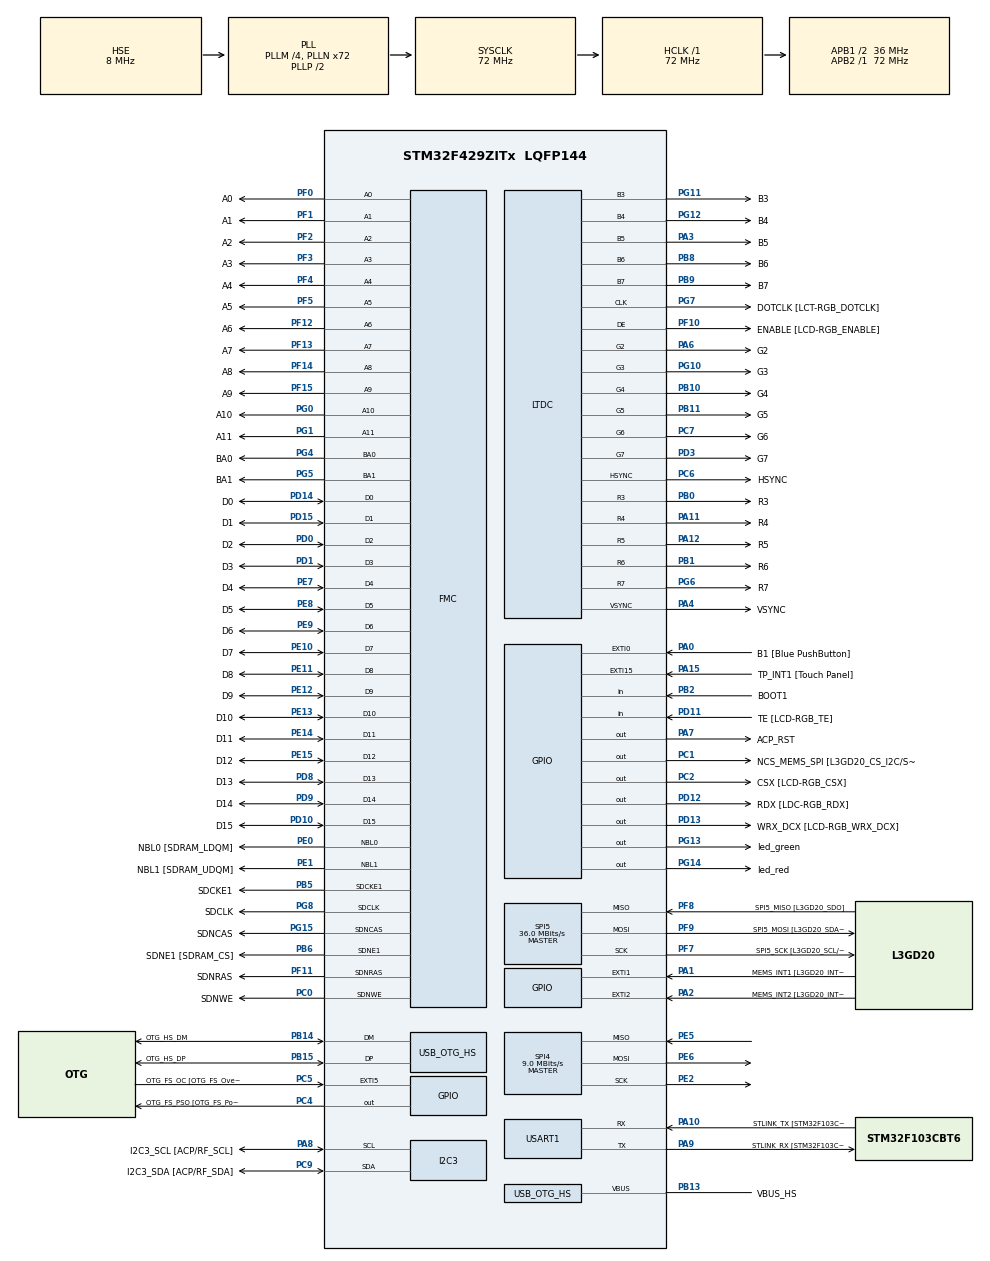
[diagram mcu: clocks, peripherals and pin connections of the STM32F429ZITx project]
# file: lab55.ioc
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FREERTOS.Tasks01=defaultTask,0,128,StartDefaultTask,Default,NULL,Dynamic,NULL,NULL
Mcu.Family=STM32F4
Mcu.Name=STM32F429ZITx
Mcu.Package=LQFP144
NVIC.OTG_HS_IRQn=true\:0\:0\:false\:false\:true\:true\:true\:true
NVIC.PriorityGroup=NVIC_PRIORITYGROUP_4
PA0/WKUP.GPIO_Label=B1 [Blue PushButton]
PA0/WKUP.GPIO_ModeDefaultEXTI=GPIO_MODE_EVT_RISING
PA0/WKUP.GPIO_PuPd=GPIO_NOPULL
PA0/WKUP.Signal=GPXTI0
PA1.GPIO_Label=MEMS_INT1 [L3GD20_INT1]
PA1.GPIO_ModeDefaultEXTI=GPIO_MODE_EVT_RISING
PA1.GPIO_PuPd=GPIO_NOPULL
PA1.Signal=GPXTI1
PA10.GPIO_Label=STLINK_TX [STM32F103CBT6_PA2]
PA10.Mode=Asynchronous
PA10.Signal=USART1_RX
PA11.GPIO_Label=R4
PA11.GPIO_Mode=GPIO_MODE_AF_PP
PA11.GPIO_PuPd=GPIO_NOPULL
PA11.GPIO_Speed=GPIO_SPEED_FREQ_LOW
PA11.Mode=RGB565
PA11.Signal=LTDC_R4
PA12.GPIO_Label=R5
PA12.GPIO_Mode=GPIO_MODE_AF_PP
PA12.GPIO_PuPd=GPIO_NOPULL
PA12.GPIO_Speed=GPIO_SPEED_FREQ_LOW
PA12.Mode=RGB565
PA12.Signal=LTDC_R5
PA13.GPIO_Label=SWDIO
PA13.Mode=Trace_Asynchronous_SW
PA13.Signal=SYS_JTMS-SWDIO
PA14.GPIO_Label=SWCLK
PA14.Mode=Trace_Asynchronous_SW
PA14.Signal=SYS_JTCK-SWCLK
PA15.GPIO_Label=TP_INT1 [Touch Panel]
PA15.GPIO_ModeDefaultEXTI=GPIO_MODE_EVT_RISING
PA15.GPIO_PuPd=GPIO_NOPULL
PA15.Signal=GPXTI15
PA2.GPIO_Label=MEMS_INT2 [L3GD20_INT2]
PA2.GPIO_ModeDefaultEXTI=GPIO_MODE_EVT_RISING
PA2.GPIO_PuPd=GPIO_NOPULL
PA2.Signal=GPXTI2
PA3.GPIO_Label=B5
PA3.GPIO_Mode=GPIO_MODE_AF_PP
PA3.GPIO_PuPd=GPIO_NOPULL
PA3.GPIO_Speed=GPIO_SPEED_FREQ_LOW
PA3.Mode=RGB565
PA3.Signal=LTDC_B5
PA4.GPIO_Label=VSYNC
PA4.GPIO_Mode=GPIO_MODE_AF_PP
PA4.GPIO_PuPd=GPIO_NOPULL
PA4.GPIO_Speed=GPIO_SPEED_FREQ_LOW
PA4.Mode=RGB565
PA4.Signal=LTDC_VSYNC
PA6.GPIO_Label=G2
PA6.GPIO_Mode=GPIO_MODE_AF_PP
PA6.GPIO_PuPd=GPIO_NOPULL
PA6.GPIO_Speed=GPIO_SPEED_FREQ_LOW
PA6.Mode=RGB565
PA6.Signal=LTDC_G2
PA7.GPIO_Label=ACP_RST
PA7.GPIO_Mode=GPIO_MODE_OUTPUT_PP
PA7.GPIO_PuPd=GPIO_NOPULL
PA7.GPIO_Speed=GPIO_SPEED_FREQ_LOW
PA7.Signal=GPIO_Output
PA8.GPIO_Label=I2C3_SCL [ACP/RF_SCL]
PA8.GPIO_Mode=GPIO_MODE_AF_OD
PA8.GPIO_Pu=GPIO_PULLUP
PA8.GPIO_PuPd=GPIO_NOPULL
PA8.GPIO_Speed=GPIO_SPEED_FREQ_LOW
PA8.Mode=I2C
PA8.Signal=I2C3_SCL
PA9.GPIO_Label=STLINK_RX [STM32F103CBT6_PA3]
PA9.Mode=Asynchronous
PA9.Signal=USART1_TX
PB0.GPIO_Label=R3
PB0.GPIO_Mode=GPIO_MODE_AF_PP
PB0.GPIO_PuPd=GPIO_NOPULL
PB0.GPIO_Speed=GPIO_SPEED_FREQ_LOW
PB0.Mode=RGB565
PB0.Signal=LTDC_R3
PB1.GPIO_Label=R6
PB1.GPIO_Mode=GPIO_MODE_AF_PP
PB1.GPIO_PuPd=GPIO_NOPULL
PB1.GPIO_Speed=GPIO_SPEED_FREQ_LOW
PB1.Mode=RGB565
PB1.Signal=LTDC_R6
PB10.GPIO_Label=G4
PB10.GPIO_Mode=GPIO_MODE_AF_PP
PB10.GPIO_PuPd=GPIO_NOPULL
PB10.GPIO_Speed=GPIO_SPEED_FREQ_LOW
PB10.Mode=RGB565
PB10.Signal=LTDC_G4
PB11.GPIO_Label=G5
PB11.GPIO_Mode=GPIO_MODE_AF_PP
PB11.GPIO_PuPd=GPIO_NOPULL
PB11.GPIO_Speed=GPIO_SPEED_FREQ_LOW
PB11.Mode=RGB565
PB11.Signal=LTDC_G5
PB12.GPIO_Label=OTG_HS_ID
PB12.GPIO_Mode=GPIO_MODE_AF_PP
PB12.GPIO_PuPd=GPIO_NOPULL
PB12.GPIO_Speed=GPIO_SPEED_FREQ_LOW
PB12.Signal=USB_OTG_HS_ID
PB13.GPIO_Label=VBUS_HS
PB13.GPIO_Mode=GPIO_MODE_INPUT
PB13.GPIO_PuPd=GPIO_NOPULL
PB13.Mode=Activate_VBUS_FS
PB13.Signal=USB_OTG_HS_VBUS
PB14.GPIO_Label=OTG_HS_DM
PB14.GPIO_Mode=GPIO_MODE_AF_PP
PB14.GPIO_PuPd=GPIO_NOPULL
PB14.GPIO_Speed=GPIO_SPEED_FREQ_LOW
PB14.Mode=Host_FS
PB14.Signal=USB_OTG_HS_DM
PB15.GPIO_Label=OTG_HS_DP
PB15.GPIO_Mode=GPIO_MODE_AF_PP
PB15.GPIO_PuPd=GPIO_NOPULL
PB15.GPIO_Speed=GPIO_SPEED_FREQ_LOW
PB15.Mode=Host_FS
PB15.Signal=USB_OTG_HS_DP
PB2/BOOT1.GPIO_Label=BOOT1
PB2/BOOT1.GPIO_Mode=GPIO_MODE_INPUT
PB2/BOOT1.GPIO_PuPd=GPIO_NOPULL
PB2/BOOT1.Signal=GPIO_Input
PB3.Mode=Trace_Asynchronous_SW
PB3.Signal=SYS_JTDO-SWO
PB5.GPIO_Label=SDCKE1
PB5.GPIO_Mode=GPIO_MODE_AF_PP
PB5.GPIO_PuPd=GPIO_NOPULL
PB5.GPIO_Speed=GPIO_SPEED_FREQ_VERY_HIGH
PB5.Mode=SdramChipSelect2_1
PB5.Signal=FMC_SDCKE1
PB6.GPIO_Label=SDNE1 [SDRAM_CS]
PB6.GPIO_Mode=GPIO_MODE_AF_PP
PB6.GPIO_PuPd=GPIO_NOPULL
PB6.GPIO_Speed=GPIO_SPEED_FREQ_VERY_HIGH
PB6.Mode=SdramChipSelect2_1
PB6.Signal=FMC_SDNE1
PB8.GPIO_Label=B6
PB8.GPIO_Mode=GPIO_MODE_AF_PP
PB8.GPIO_PuPd=GPIO_NOPULL
PB8.GPIO_Speed=GPIO_SPEED_FREQ_LOW
PB8.Mode=RGB565
PB8.Signal=LTDC_B6
PB9.GPIO_Label=B7
PB9.GPIO_Mode=GPIO_MODE_AF_PP
PB9.GPIO_PuPd=GPIO_NOPULL
PB9.GPIO_Speed=GPIO_SPEED_FREQ_LOW
PB9.Mode=RGB565
PB9.Signal=LTDC_B7
PC0.GPIO_Label=SDNWE
PC0.GPIO_Mode=GPIO_MODE_AF_PP
PC0.GPIO_PuPd=GPIO_NOPULL
PC0.GPIO_Speed=GPIO_SPEED_FREQ_VERY_HIGH
PC0.Signal=FMC_SDNWE
PC1.GPIO_Label=NCS_MEMS_SPI [L3GD20_CS_I2C/SPI]
PC1.GPIO_Mode=GPIO_MODE_OUTPUT_PP
PC1.GPIO_PuPd=GPIO_NOPULL
PC1.GPIO_Speed=GPIO_SPEED_FREQ_LOW
PC1.Signal=GPIO_Output
PC10.GPIO_Label=R2
PC10.GPIO_Mode=GPIO_MODE_AF_PP
PC10.GPIO_PuPd=GPIO_NOPULL
PC10.GPIO_Speed=GPIO_SPEED_FREQ_LOW
PC10.Signal=LTDC_R2
PC14/OSC32_IN.GPIO_Label=PC14-OSC32_IN
PC14/OSC32_IN.Signal=RCC_OSC32_IN
PC15/OSC32_OUT.GPIO_Label=PC15-OSC32_OUT
PC15/OSC32_OUT.Signal=RCC_OSC32_OUT
PC2.GPIO_Label=CSX [LCD-RGB_CSX]
PC2.GPIO_Mode=GPIO_MODE_OUTPUT_PP
PC2.GPIO_PuPd=GPIO_NOPULL
PC2.GPIO_Speed=GPIO_SPEED_FREQ_LOW
PC2.Signal=GPIO_Output
PC4.GPIO_Label=OTG_FS_PSO [OTG_FS_PowerSwitchOn]
PC4.GPIO_Mode=GPIO_MODE_OUTPUT_PP
PC4.GPIO_PuPd=GPIO_NOPULL
PC4.GPIO_Speed=GPIO_SPEED_FREQ_LOW
PC4.Signal=GPIO_Output
PC5.GPIO_Label=OTG_FS_OC [OTG_FS_OverCurrent]
PC5.GPIO_ModeDefaultEXTI=GPIO_MODE_EVT_RISING
PC5.Signal=GPXTI5
PC6.GPIO_Label=HSYNC
PC6.GPIO_Mode=GPIO_MODE_AF_PP
PC6.GPIO_PuPd=GPIO_NOPULL
PC6.GPIO_Speed=GPIO_SPEED_FREQ_LOW
PC6.Mode=RGB565
PC6.Signal=LTDC_HSYNC
PC7.GPIO_Label=G6
PC7.GPIO_Mode=GPIO_MODE_AF_PP
PC7.GPIO_PuPd=GPIO_NOPULL
PC7.GPIO_Speed=GPIO_SPEED_FREQ_LOW
PC7.Mode=RGB565
PC7.Signal=LTDC_G6
PC9.GPIO_Label=I2C3_SDA [ACP/RF_SDA]
PC9.GPIO_Mode=GPIO_MODE_AF_OD
PC9.GPIO_Pu=GPIO_PULLUP
PC9.GPIO_PuPd=GPIO_NOPULL
PC9.GPIO_Speed=GPIO_SPEED_FREQ_LOW
PC9.Mode=I2C
PC9.Signal=I2C3_SDA
PD0.GPIO_Label=D2
PD0.GPIO_Mode=GPIO_MODE_AF_PP
PD0.GPIO_PuPd=GPIO_NOPULL
PD0.GPIO_Speed=GPIO_SPEED_FREQ_VERY_HIGH
PD0.Signal=FMC_D2_DA2
PD1.GPIO_Label=D3
PD1.GPIO_Mode=GPIO_MODE_AF_PP
PD1.GPIO_PuPd=GPIO_NOPULL
PD1.GPIO_Speed=GPIO_SPEED_FREQ_VERY_HIGH
PD1.Signal=FMC_D3_DA3
PD10.GPIO_Label=D15
PD10.GPIO_Mode=GPIO_MODE_AF_PP
PD10.GPIO_PuPd=GPIO_NOPULL
PD10.GPIO_Speed=GPIO_SPEED_FREQ_VERY_HIGH
PD10.Signal=FMC_D15_DA15
PD11.GPIO_Label=TE [LCD-RGB_TE]
PD11.GPIO_Mode=GPIO_MODE_INPUT
PD11.GPIO_PuPd=GPIO_NOPULL
PD11.Signal=GPIO_Input
PD12.GPIO_Label=RDX [LDC-RGB_RDX]
PD12.GPIO_Mode=GPIO_MODE_OUTPUT_PP
PD12.GPIO_PuPd=GPIO_NOPULL
PD12.GPIO_Speed=GPIO_SPEED_FREQ_LOW
PD12.Signal=GPIO_Output
PD13.GPIO_Label=WRX_DCX [LCD-RGB_WRX_DCX]
PD13.GPIO_Mode=GPIO_MODE_OUTPUT_PP
PD13.GPIO_PuPd=GPIO_NOPULL
PD13.GPIO_Speed=GPIO_SPEED_FREQ_LOW
PD13.Signal=GPIO_Output
PD14.GPIO_Label=D0
PD14.GPIO_Mode=GPIO_MODE_AF_PP
PD14.GPIO_PuPd=GPIO_NOPULL
PD14.GPIO_Speed=GPIO_SPEED_FREQ_VERY_HIGH
PD14.Signal=FMC_D0_DA0
PD15.GPIO_Label=D1
PD15.GPIO_Mode=GPIO_MODE_AF_PP
PD15.GPIO_PuPd=GPIO_NOPULL
PD15.GPIO_Speed=GPIO_SPEED_FREQ_VERY_HIGH
PD15.Signal=FMC_D1_DA1
PD3.GPIO_Label=G7
PD3.GPIO_Mode=GPIO_MODE_AF_PP
PD3.GPIO_PuPd=GPIO_NOPULL
PD3.GPIO_Speed=GPIO_SPEED_FREQ_LOW
PD3.Mode=RGB565
PD3.Signal=LTDC_G7
PD6.GPIO_Label=B2
PD6.GPIO_Mode=GPIO_MODE_AF_PP
PD6.GPIO_PuPd=GPIO_NOPULL
PD6.GPIO_Speed=GPIO_SPEED_FREQ_LOW
PD6.Signal=LTDC_B2
PD8.GPIO_Label=D13
PD8.GPIO_Mode=GPIO_MODE_AF_PP
PD8.GPIO_PuPd=GPIO_NOPULL
PD8.GPIO_Speed=GPIO_SPEED_FREQ_VERY_HIGH
PD8.Signal=FMC_D13_DA13
PD9.GPIO_Label=D14
PD9.GPIO_Mode=GPIO_MODE_AF_PP
PD9.GPIO_PuPd=GPIO_NOPULL
PD9.GPIO_Speed=GPIO_SPEED_FREQ_VERY_HIGH
PD9.Signal=FMC_D14_DA14
PE0.GPIO_Label=NBL0 [SDRAM_LDQM]
PE0.GPIO_Mode=GPIO_MODE_AF_PP
PE0.GPIO_PuPd=GPIO_NOPULL
PE0.GPIO_Speed=GPIO_SPEED_FREQ_VERY_HIGH
PE0.Signal=FMC_NBL0
PE1.GPIO_Label=NBL1 [SDRAM_UDQM]
PE1.GPIO_Mode=GPIO_MODE_AF_PP
PE1.GPIO_PuPd=GPIO_NOPULL
PE1.GPIO_Speed=GPIO_SPEED_FREQ_VERY_HIGH
PE1.Signal=FMC_NBL1
PE10.GPIO_Label=D7
PE10.GPIO_Mode=GPIO_MODE_AF_PP
PE10.GPIO_PuPd=GPIO_NOPULL
PE10.GPIO_Speed=GPIO_SPEED_FREQ_VERY_HIGH
PE10.Signal=FMC_D7_DA7
PE11.GPIO_Label=D8
PE11.GPIO_Mode=GPIO_MODE_AF_PP
PE11.GPIO_PuPd=GPIO_NOPULL
PE11.GPIO_Speed=GPIO_SPEED_FREQ_VERY_HIGH
PE11.Signal=FMC_D8_DA8
PE12.GPIO_Label=D9
PE12.GPIO_Mode=GPIO_MODE_AF_PP
PE12.GPIO_PuPd=GPIO_NOPULL
PE12.GPIO_Speed=GPIO_SPEED_FREQ_VERY_HIGH
PE12.Signal=FMC_D9_DA9
PE13.GPIO_Label=D10
PE13.GPIO_Mode=GPIO_MODE_AF_PP
PE13.GPIO_PuPd=GPIO_NOPULL
PE13.GPIO_Speed=GPIO_SPEED_FREQ_VERY_HIGH
PE13.Signal=FMC_D10_DA10
PE14.GPIO_Label=D11
PE14.GPIO_Mode=GPIO_MODE_AF_PP
PE14.GPIO_PuPd=GPIO_NOPULL
PE14.GPIO_Speed=GPIO_SPEED_FREQ_VERY_HIGH
PE14.Signal=FMC_D11_DA11
PE15.GPIO_Label=D12
PE15.GPIO_Mode=GPIO_MODE_AF_PP
PE15.GPIO_PuPd=GPIO_NOPULL
PE15.GPIO_Speed=GPIO_SPEED_FREQ_VERY_HIGH
PE15.Signal=FMC_D12_DA12
PE2.Mode=Full_Duplex_Master
PE2.Signal=SPI4_SCK
PE5.Mode=Full_Duplex_Master
PE5.Signal=SPI4_MISO
PE6.Mode=Full_Duplex_Master
PE6.Signal=SPI4_MOSI
PE7.GPIO_Label=D4
PE7.GPIO_Mode=GPIO_MODE_AF_PP
PE7.GPIO_PuPd=GPIO_NOPULL
PE7.GPIO_Speed=GPIO_SPEED_FREQ_VERY_HIGH
PE7.Signal=FMC_D4_DA4
PE8.GPIO_Label=D5
PE8.GPIO_Mode=GPIO_MODE_AF_PP
PE8.GPIO_PuPd=GPIO_NOPULL
PE8.GPIO_Speed=GPIO_SPEED_FREQ_VERY_HIGH
PE8.Signal=FMC_D5_DA5
PE9.GPIO_Label=D6
PE9.GPIO_Mode=GPIO_MODE_AF_PP
PE9.GPIO_PuPd=GPIO_NOPULL
PE9.GPIO_Speed=GPIO_SPEED_FREQ_VERY_HIGH
PE9.Signal=FMC_D6_DA6
PF0.GPIO_Label=A0
PF0.GPIO_Mode=GPIO_MODE_AF_PP
PF0.GPIO_PuPd=GPIO_NOPULL
PF0.GPIO_Speed=GPIO_SPEED_FREQ_VERY_HIGH
PF0.Signal=FMC_A0
PF1.GPIO_Label=A1
PF1.GPIO_Mode=GPIO_MODE_AF_PP
PF1.GPIO_PuPd=GPIO_NOPULL
PF1.GPIO_Speed=GPIO_SPEED_FREQ_VERY_HIGH
PF1.Signal=FMC_A1
PF10.GPIO_Label=ENABLE [LCD-RGB_ENABLE]
PF10.GPIO_Mode=GPIO_MODE_AF_PP
PF10.GPIO_PuPd=GPIO_NOPULL
PF10.GPIO_Speed=GPIO_SPEED_FREQ_LOW
PF10.Mode=RGB565
PF10.Signal=LTDC_DE
PF11.GPIO_Label=SDNRAS
PF11.GPIO_Mode=GPIO_MODE_AF_PP
PF11.GPIO_PuPd=GPIO_NOPULL
PF11.GPIO_Speed=GPIO_SPEED_FREQ_VERY_HIGH
PF11.Signal=FMC_SDNRAS
PF12.GPIO_Label=A6
PF12.GPIO_Mode=GPIO_MODE_AF_PP
PF12.GPIO_PuPd=GPIO_NOPULL
PF12.GPIO_Speed=GPIO_SPEED_FREQ_VERY_HIGH
PF12.Signal=FMC_A6
PF13.GPIO_Label=A7
PF13.GPIO_Mode=GPIO_MODE_AF_PP
PF13.GPIO_PuPd=GPIO_NOPULL
PF13.GPIO_Speed=GPIO_SPEED_FREQ_VERY_HIGH
PF13.Signal=FMC_A7
PF14.GPIO_Label=A8
PF14.GPIO_Mode=GPIO_MODE_AF_PP
PF14.GPIO_PuPd=GPIO_NOPULL
PF14.GPIO_Speed=GPIO_SPEED_FREQ_VERY_HIGH
PF14.Signal=FMC_A8
PF15.GPIO_Label=A9
PF15.GPIO_Mode=GPIO_MODE_AF_PP
PF15.GPIO_PuPd=GPIO_NOPULL
PF15.GPIO_Speed=GPIO_SPEED_FREQ_VERY_HIGH
PF15.Signal=FMC_A9
PF2.GPIO_Label=A2
PF2.GPIO_Mode=GPIO_MODE_AF_PP
PF2.GPIO_PuPd=GPIO_NOPULL
PF2.GPIO_Speed=GPIO_SPEED_FREQ_VERY_HIGH
PF2.Signal=FMC_A2
PF3.GPIO_Label=A3
PF3.GPIO_Mode=GPIO_MODE_AF_PP
PF3.GPIO_PuPd=GPIO_NOPULL
PF3.GPIO_Speed=GPIO_SPEED_FREQ_VERY_HIGH
PF3.Signal=FMC_A3
PF4.GPIO_Label=A4
PF4.GPIO_Mode=GPIO_MODE_AF_PP
PF4.GPIO_PuPd=GPIO_NOPULL
PF4.GPIO_Speed=GPIO_SPEED_FREQ_VERY_HIGH
PF4.Signal=FMC_A4
PF5.GPIO_Label=A5
PF5.GPIO_Mode=GPIO_MODE_AF_PP
PF5.GPIO_PuPd=GPIO_NOPULL
PF5.GPIO_Speed=GPIO_SPEED_FREQ_VERY_HIGH
PF5.Signal=FMC_A5
PF7.GPIO_Label=SPI5_SCK [L3GD20_SCL/SPC]
PF7.GPIO_Mode=GPIO_MODE_AF_PP
PF7.GPIO_PuPd=GPIO_NOPULL
PF7.GPIO_Speed=GPIO_SPEED_FREQ_LOW
PF7.Mode=Full_Duplex_Master
PF7.Signal=SPI5_SCK
PF8.GPIO_Label=SPI5_MISO [L3GD20_SDO]
PF8.GPIO_Mode=GPIO_MODE_AF_PP
PF8.GPIO_PuPd=GPIO_NOPULL
PF8.GPIO_Speed=GPIO_SPEED_FREQ_LOW
PF8.Mode=Full_Duplex_Master
PF8.Signal=SPI5_MISO
PF9.GPIO_Label=SPI5_MOSI [L3GD20_SDA/SDI/SDO]
PF9.GPIO_Mode=GPIO_MODE_AF_PP
PF9.GPIO_PuPd=GPIO_NOPULL
PF9.GPIO_Speed=GPIO_SPEED_FREQ_LOW
PF9.Mode=Full_Duplex_Master
PF9.Signal=SPI5_MOSI
PG0.GPIO_Label=A10
PG0.GPIO_Mode=GPIO_MODE_AF_PP
PG0.GPIO_PuPd=GPIO_NOPULL
PG0.GPIO_Speed=GPIO_SPEED_FREQ_VERY_HIGH
PG0.Signal=FMC_A10
PG1.GPIO_Label=A11
PG1.GPIO_Mode=GPIO_MODE_AF_PP
PG1.GPIO_PuPd=GPIO_NOPULL
PG1.GPIO_Speed=GPIO_SPEED_FREQ_VERY_HIGH
PG1.Signal=FMC_A11
PG10.GPIO_Label=G3
PG10.GPIO_Mode=GPIO_MODE_AF_PP
PG10.GPIO_PuPd=GPIO_NOPULL
PG10.GPIO_Speed=GPIO_SPEED_FREQ_LOW
PG10.Mode=RGB565
PG10.Signal=LTDC_G3
PG11.GPIO_Label=B3
PG11.GPIO_Mode=GPIO_MODE_AF_PP
PG11.GPIO_PuPd=GPIO_NOPULL
PG11.GPIO_Speed=GPIO_SPEED_FREQ_LOW
PG11.Mode=RGB565
PG11.Signal=LTDC_B3
PG12.GPIO_Label=B4
PG12.GPIO_Mode=GPIO_MODE_AF_PP
PG12.GPIO_PuPd=GPIO_NOPULL
PG12.GPIO_Speed=GPIO_SPEED_FREQ_LOW
PG12.Mode=RGB565
PG12.Signal=LTDC_B4
PG13.GPIO_Label=led_green
PG13.GPIO_Mode=GPIO_MODE_OUTPUT_PP
PG13.GPIO_PuPd=GPIO_NOPULL
PG13.GPIO_Speed=GPIO_SPEED_FREQ_LOW
PG13.Signal=GPIO_Output
PG14.GPIO_Label=led_red
PG14.GPIO_Mode=GPIO_MODE_OUTPUT_PP
PG14.GPIO_PuPd=GPIO_NOPULL
PG14.GPIO_Speed=GPIO_SPEED_FREQ_LOW
PG14.Signal=GPIO_Output
PG15.GPIO_Label=SDNCAS
PG15.GPIO_Mode=GPIO_MODE_AF_PP
PG15.GPIO_PuPd=GPIO_NOPULL
PG15.GPIO_Speed=GPIO_SPEED_FREQ_VERY_HIGH
PG15.Signal=FMC_SDNCAS
PG4.GPIO_Label=BA0
PG4.GPIO_Mode=GPIO_MODE_AF_PP
PG4.GPIO_PuPd=GPIO_NOPULL
PG4.GPIO_Speed=GPIO_SPEED_FREQ_VERY_HIGH
PG4.Signal=FMC_A14_BA0
PG5.GPIO_Label=BA1
PG5.GPIO_Mode=GPIO_MODE_AF_PP
PG5.GPIO_PuPd=GPIO_NOPULL
PG5.GPIO_Speed=GPIO_SPEED_FREQ_VERY_HIGH
PG5.Signal=FMC_A15_BA1
PG6.GPIO_Label=R7
PG6.GPIO_Mode=GPIO_MODE_AF_PP
PG6.GPIO_PuPd=GPIO_NOPULL
PG6.GPIO_Speed=GPIO_SPEED_FREQ_LOW
PG6.Mode=RGB565
PG6.Signal=LTDC_R7
PG7.GPIO_Label=DOTCLK [LCT-RGB_DOTCLK]
PG7.GPIO_Mode=GPIO_MODE_AF_PP
PG7.GPIO_PuPd=GPIO_NOPULL
PG7.GPIO_Speed=GPIO_SPEED_FREQ_LOW
PG7.Mode=RGB565
PG7.Signal=LTDC_CLK
PG8.GPIO_Label=SDCLK
PG8.GPIO_Mode=GPIO_MODE_AF_PP
PG8.GPIO_PuPd=GPIO_NOPULL
PG8.GPIO_Speed=GPIO_SPEED_FREQ_VERY_HIGH
PG8.Signal=FMC_SDCLK
PH0/OSC_IN.GPIO_Label=PH0-OSC_IN
PH0/OSC_IN.Mode=HSE-External-Oscillator
PH0/OSC_IN.Signal=RCC_OSC_IN
PH1/OSC_OUT.GPIO_Label=PH1-OSC_OUT
PH1/OSC_OUT.Mode=HSE-External-Oscillator
PH1/OSC_OUT.Signal=RCC_OSC_OUT
ProjectManager.HeapSize=0x200
ProjectManager.StackSize=0x400
ProjectManager.TargetToolchain=STM32CubeIDE
RCC.48MHZClocksFreq_Value=48000000
RCC.AHBFreq_Value=72000000
RCC.APB1CLKDivider=RCC_HCLK_DIV2
RCC.APB1Freq_Value=36000000
RCC.APB1TimFreq_Value=72000000
RCC.APB2Freq_Value=72000000
RCC.APB2TimFreq_Value=72000000
RCC.CortexFreq_Value=72000000
RCC.HCLKFreq_Value=72000000
RCC.HSE_VALUE=8000000
RCC.HSI_VALUE=16000000
RCC.LSE_VALUE=32768
RCC.PLLM=4
RCC.PLLN=72
RCC.PLLQ=3
RCC.PLLSAIN=50
RCC.SYSCLKFreq_VALUE=72000000
RCC.SYSCLKSource=RCC_SYSCLKSOURCE_PLLCLK
RCC.VCOOutputFreq_Value=144000000
SH.FMC_A0.0=FMC_A0,12b-sda1
SH.FMC_A1.0=FMC_A1,12b-sda1
SH.FMC_A10.0=FMC_A10,12b-sda1
SH.FMC_A11.0=FMC_A11,12b-sda1
SH.FMC_A14_BA0.0=FMC_BA0,FourSdramBanks1
SH.FMC_A15_BA1.0=FMC_BA1,FourSdramBanks1
SH.FMC_A2.0=FMC_A2,12b-sda1
SH.FMC_A3.0=FMC_A3,12b-sda1
SH.FMC_A4.0=FMC_A4,12b-sda1
SH.FMC_A5.0=FMC_A5,12b-sda1
SH.FMC_A6.0=FMC_A6,12b-sda1
SH.FMC_A7.0=FMC_A7,12b-sda1
SH.FMC_A8.0=FMC_A8,12b-sda1
SH.FMC_A9.0=FMC_A9,12b-sda1
SH.FMC_D0_DA0.0=FMC_D0,sd-16b-d1
SH.FMC_D10_DA10.0=FMC_D10,sd-16b-d1
SH.FMC_D11_DA11.0=FMC_D11,sd-16b-d1
SH.FMC_D12_DA12.0=FMC_D12,sd-16b-d1
SH.FMC_D13_DA13.0=FMC_D13,sd-16b-d1
SH.FMC_D14_DA14.0=FMC_D14,sd-16b-d1
SH.FMC_D15_DA15.0=FMC_D15,sd-16b-d1
SH.FMC_D1_DA1.0=FMC_D1,sd-16b-d1
SH.FMC_D2_DA2.0=FMC_D2,sd-16b-d1
SH.FMC_D3_DA3.0=FMC_D3,sd-16b-d1
SH.FMC_D4_DA4.0=FMC_D4,sd-16b-d1
SH.FMC_D5_DA5.0=FMC_D5,sd-16b-d1
SH.FMC_D6_DA6.0=FMC_D6,sd-16b-d1
SH.FMC_D7_DA7.0=FMC_D7,sd-16b-d1
SH.FMC_D8_DA8.0=FMC_D8,sd-16b-d1
SH.FMC_D9_DA9.0=FMC_D9,sd-16b-d1
SH.FMC_NBL0.0=FMC_NBL0,Sd2ByteEnable1
SH.FMC_NBL1.0=FMC_NBL1,Sd2ByteEnable1
SH.FMC_SDCLK.0=FMC_SDCLK,12b-sda1
SH.FMC_SDNCAS.0=FMC_SDNCAS,12b-sda1
SH.FMC_SDNRAS.0=FMC_SDNRAS,12b-sda1
SH.FMC_SDNWE.0=FMC_SDNWE,12b-sda1
SPI4.BaudRatePrescaler=SPI_BAUDRATEPRESCALER_8
SPI4.CalculateBaudRate=9.0 MBits/s
SPI4.Direction=SPI_DIRECTION_2LINES
SPI4.Mode=SPI_MODE_MASTER
SPI4.VirtualType=VM_MASTER
SPI5.CalculateBaudRate=36.0 MBits/s
SPI5.Direction=SPI_DIRECTION_2LINES
SPI5.Mode=SPI_MODE_MASTER
SPI5.VirtualType=VM_MASTER
USART1.VirtualMode=VM_ASYNC
USB_HOST.USBH_HandleTypeDef-CDC_HS=hUsbHostHS
USB_HOST.VirtualModeHS=Cdc
USB_OTG_HS.VirtualMode-Host_FS=Host_FS
VP_CRC_VS_CRC.Mode=CRC_Activate
VP_DMA2D_VS_DMA2D.Mode=DMA2D_Activate
VP_FREERTOS_VS_CMSIS_V1.Mode=CMSIS_V1
VP_TIM1_VS_ClockSourceINT.Mode=Internal
VP_USB_HOST_VS_USB_HOST_CDC_HS.Mode=CDC_HS
board=STM32F429I-DISC1

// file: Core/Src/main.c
/* USER CODE BEGIN Header */
/**
  ******************************************************************************
  * @file           : main.c
  * @brief          : Main program body
  ******************************************************************************
  * @attention
  *
  * Copyright (c) 2026 STMicroelectronics.
  * All rights reserved.
  *
  * This software is licensed under terms that can be found in the LICENSE file
  * in the root directory of this software component.
  * If no LICENSE file comes with this software, it is provided AS-IS.
  *
  ******************************************************************************
  */
/* USER CODE END Header */
#include "main.h"
#include "cmsis_os.h"
#include "usb_host.h"

/* USER CODE BEGIN Includes */
#include <stdio.h>
#include <string.h>
/* USER CODE END Includes */

/* USER CODE BEGIN PD */
#define CSX_Pin        GPIO_PIN_2
#define WRX_DCX_Pin    GPIO_PIN_13
/* ILI9341 komandos */
#define ILI9341_RESET           0x01
#define ILI9341_SLEEP_OUT       0x11
#define ILI9341_GAMMA           0x26
#define ILI9341_DISPLAY_OFF     0x28
#define ILI9341_DISPLAY_ON      0x29
#define ILI9341_COLUMN_ADDR     0x2A
#define ILI9341_PAGE_ADDR       0x2B
#define ILI9341_GRAM            0x2C
#define ILI9341_MAC             0x36
#define ILI9341_PIXEL_FORMAT    0x3A
#define ILI9341_WDB             0x51
#define ILI9341_WCD             0x53
#define ILI9341_RGB_INTERFACE   0xB0
#define ILI9341_FRC             0xB1
#define ILI9341_BPC             0xB5
#define ILI9341_DFC             0xB6
#define ILI9341_POWER1          0xC0
#define ILI9341_POWER2          0xC1
#define ILI9341_VCOM1           0xC5
#define ILI9341_VCOM2           0xC7
#define ILI9341_POWERA          0xCB
#define ILI9341_POWERB          0xCF
#define ILI9341_PGAMMA          0xE0
#define ILI9341_NGAMMA          0xE1
#define ILI9341_DTCA            0xE8
#define ILI9341_DTCB            0xEA
#define ILI9341_POWER_SEQ       0xED
#define ILI9341_3GAMMA_EN       0xF2
#define ILI9341_INTERFACE       0xF6
#define ILI9341_PRC             0xF7

/* Ekrano dydis */
#define LCD_WIDTH   240
#define LCD_HEIGHT  320

/* Spalvos RGB565 formatu */
#define COLOR_BLACK   0x0000
#define COLOR_WHITE   0xFFFF
#define COLOR_RED     0xF800
#define COLOR_GREEN   0x07E0
#define COLOR_BLUE    0x001F
#define COLOR_YELLOW  0xFFE0
#define COLOR_CYAN    0x07FF
#define COLOR_MAGENTA 0xF81F

/* GPIO – atitinka jūsų MX_GPIO_Init konfigūraciją */
#define LCD_CS_LOW()   HAL_GPIO_WritePin(GPIOC, CSX_Pin,      GPIO_PIN_RESET)
#define LCD_CS_HIGH()  HAL_GPIO_WritePin(GPIOC, CSX_Pin,      GPIO_PIN_SET)
#define LCD_DC_LOW()   HAL_GPIO_WritePin(GPIOD, WRX_DCX_Pin,  GPIO_PIN_RESET)  /* komanda */
#define LCD_DC_HIGH()  HAL_GPIO_WritePin(GPIOD, WRX_DCX_Pin,  GPIO_PIN_SET)    /* duomenys */
#define LCD_RST_LOW()  HAL_GPIO_WritePin(ACP_RST_GPIO_Port, ACP_RST_Pin, GPIO_PIN_RESET)
#define LCD_RST_HIGH() HAL_GPIO_WritePin(ACP_RST_GPIO_Port, ACP_RST_Pin, GPIO_PIN_SET)
/* USER CODE END PD */

CRC_HandleTypeDef hcrc;

DMA2D_HandleTypeDef hdma2d;

I2C_HandleTypeDef hi2c3;

LTDC_HandleTypeDef hltdc;

SPI_HandleTypeDef hspi4;
SPI_HandleTypeDef hspi5;

TIM_HandleTypeDef htim1;

UART_HandleTypeDef huart1;

SDRAM_HandleTypeDef hsdram1;

osThreadId defaultTaskHandle;
/* USER CODE BEGIN PV */
uint8_t tx_data[4] = {8, 12, 13, 15}; // Duomenys, kuriuos siųsime
uint8_t rx_data[4] = {0, 0, 0, 0};     // Čia saugosime tai, ką priimsime
HAL_StatusTypeDef spi_status = HAL_OK;  // add this
/* USER CODE END PV */

void SystemClock_Config(void);
static void MX_GPIO_Init(void);
static void MX_CRC_Init(void);
static void MX_DMA2D_Init(void);
static void MX_FMC_Init(void);
static void MX_I2C3_Init(void);
static void MX_LTDC_Init(void);
static void MX_SPI4_Init(void);
static void MX_SPI5_Init(void);
static void MX_TIM1_Init(void);
static void MX_USART1_UART_Init(void);
void StartDefaultTask(void const * argument);

/* USER CODE BEGIN PFP */
static void LCD_WriteCommand(uint8_t cmd);
static void LCD_WriteData(uint8_t data);
static void LCD_WriteData16(uint16_t data);
static void LCD_Init(void);
static void LCD_SetWindow(uint16_t x0, uint16_t y0, uint16_t x1, uint16_t y1);
static void LCD_FillRect(uint16_t x, uint16_t y, uint16_t w, uint16_t h, uint16_t color);
static void LCD_FillScreen(uint16_t color);
static void LCD_DrawChar(uint16_t x, uint16_t y, char c, uint16_t fg, uint16_t bg, uint8_t size);
static void LCD_DrawString(uint16_t x, uint16_t y, const char *str, uint16_t fg, uint16_t bg, uint8_t size);
static void LCD_DrawPixel(uint16_t x, uint16_t y, uint16_t color);
static void LCD_DrawLine(uint16_t x0, uint16_t y0, uint16_t x1, uint16_t y1, uint16_t color);
static void LCD_DrawRect(uint16_t x, uint16_t y, uint16_t w, uint16_t h, uint16_t color);
static void SPI_Demo_Display(uint8_t *tx, uint8_t *rx, HAL_StatusTypeDef status);
/* USER CODE END PFP */

int main(void)
{

  /* MCU Configuration--------------------------------------------------------*/

  /* Reset of all peripherals, Initializes the Flash interface and the Systick. */
  HAL_Init();

  /* Configure the system clock */
  SystemClock_Config();

  /* Initialize all configured peripherals */
  MX_GPIO_Init();
  MX_CRC_Init();
  MX_DMA2D_Init();
 // MX_FMC_Init();
  MX_I2C3_Init();
 // MX_LTDC_Init();
  MX_SPI4_Init();
  MX_SPI5_Init();
  MX_TIM1_Init();
  MX_USART1_UART_Init();
  /* USER CODE BEGIN 2 */
  HAL_SPI_TransmitReceive(&hspi4, tx_data, rx_data, 4, 100);
  /* USER CODE END 2 */

  /* Create the thread(s) */
  /* definition and creation of defaultTask */
  osThreadDef(defaultTask, StartDefaultTask, osPriorityNormal, 0, 128);
//  defaultTaskHandle = osThreadCreate(osThread(defaultTask), NULL);

  /* USER CODE BEGIN RTOS_THREADS */
  if(defaultTaskHandle == NULL)
      {
          // Task nesukurtas - mirksėkite raudonai
          while(1)
          {
              HAL_GPIO_TogglePin(GPIOG, led_red_Pin);
              HAL_Delay(200);
          }
      }
  /* USER CODE END RTOS_THREADS */

  /* Start scheduler */
  osKernelStart();

  /* We should never get here as control is now taken by the scheduler */

  /* Infinite loop */
  while (1)
  {
	      {
	          HAL_GPIO_TogglePin(GPIOG, led_green_Pin);
	          HAL_Delay(500);
	      }
  }
}

void SystemClock_Config(void)
{
  RCC_OscInitTypeDef RCC_OscInitStruct = {0};
  RCC_ClkInitTypeDef RCC_ClkInitStruct = {0};

  /** Configure the main internal regulator output voltage
  */
  __HAL_RCC_PWR_CLK_ENABLE();
  __HAL_PWR_VOLTAGESCALING_CONFIG(PWR_REGULATOR_VOLTAGE_SCALE3);

  /** Initializes the RCC Oscillators according to the specified parameters
  * in the RCC_OscInitTypeDef structure.
  */
  RCC_OscInitStruct.OscillatorType = RCC_OSCILLATORTYPE_HSE;
  RCC_OscInitStruct.HSEState = RCC_HSE_ON;
  RCC_OscInitStruct.PLL.PLLState = RCC_PLL_ON;
  RCC_OscInitStruct.PLL.PLLSource = RCC_PLLSOURCE_HSE;
  RCC_OscInitStruct.PLL.PLLM = 4;
  RCC_OscInitStruct.PLL.PLLN = 72;
  RCC_OscInitStruct.PLL.PLLP = RCC_PLLP_DIV2;
  RCC_OscInitStruct.PLL.PLLQ = 3;
  if (HAL_RCC_OscConfig(&RCC_OscInitStruct) != HAL_OK)
  {
    Error_Handler();
  }

  /** Initializes the CPU, AHB and APB buses clocks
  */
  RCC_ClkInitStruct.ClockType = RCC_CLOCKTYPE_HCLK|RCC_CLOCKTYPE_SYSCLK
                              |RCC_CLOCKTYPE_PCLK1|RCC_CLOCKTYPE_PCLK2;
  RCC_ClkInitStruct.SYSCLKSource = RCC_SYSCLKSOURCE_PLLCLK;
  RCC_ClkInitStruct.AHBCLKDivider = RCC_SYSCLK_DIV1;
  RCC_ClkInitStruct.APB1CLKDivider = RCC_HCLK_DIV2;
  RCC_ClkInitStruct.APB2CLKDivider = RCC_HCLK_DIV1;

  if (HAL_RCC_ClockConfig(&RCC_ClkInitStruct, FLASH_LATENCY_2) != HAL_OK)
  {
    Error_Handler();
  }
}

static void MX_CRC_Init(void)
{

  hcrc.Instance = CRC;
  if (HAL_CRC_Init(&hcrc) != HAL_OK)
  {
    Error_Handler();
  }

}

static void MX_DMA2D_Init(void)
{

  hdma2d.Instance = DMA2D;
  hdma2d.Init.Mode = DMA2D_M2M;
  hdma2d.Init.ColorMode = DMA2D_OUTPUT_ARGB8888;
  hdma2d.Init.OutputOffset = 0;
  hdma2d.LayerCfg[1].InputOffset = 0;
  hdma2d.LayerCfg[1].InputColorMode = DMA2D_INPUT_ARGB8888;
  hdma2d.LayerCfg[1].AlphaMode = DMA2D_NO_MODIF_ALPHA;
  hdma2d.LayerCfg[1].InputAlpha = 0;
  if (HAL_DMA2D_Init(&hdma2d) != HAL_OK)
  {
    Error_Handler();
  }
  if (HAL_DMA2D_ConfigLayer(&hdma2d, 1) != HAL_OK)
  {
    Error_Handler();
  }

}

static void MX_I2C3_Init(void)
{

  hi2c3.Instance = I2C3;
  hi2c3.Init.ClockSpeed = 100000;
  hi2c3.Init.DutyCycle = I2C_DUTYCYCLE_2;
  hi2c3.Init.OwnAddress1 = 0;
  hi2c3.Init.AddressingMode = I2C_ADDRESSINGMODE_7BIT;
  hi2c3.Init.DualAddressMode = I2C_DUALADDRESS_DISABLE;
  hi2c3.Init.OwnAddress2 = 0;
  hi2c3.Init.GeneralCallMode = I2C_GENERALCALL_DISABLE;
  hi2c3.Init.NoStretchMode = I2C_NOSTRETCH_DISABLE;
  if (HAL_I2C_Init(&hi2c3) != HAL_OK)
  {
    Error_Handler();
  }

  /** Configure Analogue filter
  */
  if (HAL_I2CEx_ConfigAnalogFilter(&hi2c3, I2C_ANALOGFILTER_ENABLE) != HAL_OK)
  {
    Error_Handler();
  }

  /** Configure Digital filter
  */
  if (HAL_I2CEx_ConfigDigitalFilter(&hi2c3, 0) != HAL_OK)
  {
    Error_Handler();
  }

}

static void MX_LTDC_Init(void)
{

  LTDC_LayerCfgTypeDef pLayerCfg = {0};
  LTDC_LayerCfgTypeDef pLayerCfg1 = {0};

  hltdc.Instance = LTDC;
  hltdc.Init.HSPolarity = LTDC_HSPOLARITY_AL;
  hltdc.Init.VSPolarity = LTDC_VSPOLARITY_AL;
  hltdc.Init.DEPolarity = LTDC_DEPOLARITY_AL;
  hltdc.Init.PCPolarity = LTDC_PCPOLARITY_IPC;
  hltdc.Init.HorizontalSync = 7;
  hltdc.Init.VerticalSync = 3;
  hltdc.Init.AccumulatedHBP = 14;
  hltdc.Init.AccumulatedVBP = 5;
  hltdc.Init.AccumulatedActiveW = 654;
  hltdc.Init.AccumulatedActiveH = 485;
  hltdc.Init.TotalWidth = 660;
  hltdc.Init.TotalHeigh = 487;
  hltdc.Init.Backcolor.Blue = 0;
  hltdc.Init.Backcolor.Green = 0;
  hltdc.Init.Backcolor.Red = 0;
  if (HAL_LTDC_Init(&hltdc) != HAL_OK)
  {
    Error_Handler();
  }
  pLayerCfg.WindowX0 = 0;
  pLayerCfg.WindowX1 = 0;
  pLayerCfg.WindowY0 = 0;
  pLayerCfg.WindowY1 = 0;
  pLayerCfg.PixelFormat = LTDC_PIXEL_FORMAT_ARGB8888;
  pLayerCfg.Alpha = 0;
  pLayerCfg.Alpha0 = 0;
  pLayerCfg.BlendingFactor1 = LTDC_BLENDING_FACTOR1_CA;
  pLayerCfg.BlendingFactor2 = LTDC_BLENDING_FACTOR2_CA;
  pLayerCfg.FBStartAdress = 0;
  pLayerCfg.ImageWidth = 0;
  pLayerCfg.ImageHeight = 0;
  pLayerCfg.Backcolor.Blue = 0;
  pLayerCfg.Backcolor.Green = 0;
  pLayerCfg.Backcolor.Red = 0;
  if (HAL_LTDC_ConfigLayer(&hltdc, &pLayerCfg, 0) != HAL_OK)
  {
    Error_Handler();
  }
  pLayerCfg1.WindowX0 = 0;
  pLayerCfg1.WindowX1 = 0;
  pLayerCfg1.WindowY0 = 0;
  pLayerCfg1.WindowY1 = 0;
  pLayerCfg1.PixelFormat = LTDC_PIXEL_FORMAT_ARGB8888;
  pLayerCfg1.Alpha = 0;
  pLayerCfg1.Alpha0 = 0;
  pLayerCfg1.BlendingFactor1 = LTDC_BLENDING_FACTOR1_CA;
  pLayerCfg1.BlendingFactor2 = LTDC_BLENDING_FACTOR2_CA;
  pLayerCfg1.FBStartAdress = 0;
  pLayerCfg1.ImageWidth = 0;
  pLayerCfg1.ImageHeight = 0;
  pLayerCfg1.Backcolor.Blue = 0;
  pLayerCfg1.Backcolor.Green = 0;
  pLayerCfg1.Backcolor.Red = 0;
  if (HAL_LTDC_ConfigLayer(&hltdc, &pLayerCfg1, 1) != HAL_OK)
  {
    Error_Handler();
  }

}

static void MX_SPI4_Init(void)
{

  /* SPI4 parameter configuration*/
  hspi4.Instance = SPI4;
  hspi4.Init.Mode = SPI_MODE_MASTER;
  hspi4.Init.Direction = SPI_DIRECTION_2LINES;
  hspi4.Init.DataSize = SPI_DATASIZE_8BIT;
  hspi4.Init.CLKPolarity = SPI_POLARITY_LOW;
  hspi4.Init.CLKPhase = SPI_PHASE_1EDGE;
  hspi4.Init.NSS = SPI_NSS_SOFT;
  hspi4.Init.BaudRatePrescaler = SPI_BAUDRATEPRESCALER_8;
  hspi4.Init.FirstBit = SPI_FIRSTBIT_MSB;
  hspi4.Init.TIMode = SPI_TIMODE_DISABLE;
  hspi4.Init.CRCCalculation = SPI_CRCCALCULATION_DISABLE;
  hspi4.Init.CRCPolynomial = 10;
  if (HAL_SPI_Init(&hspi4) != HAL_OK)
  {
    Error_Handler();
  }

}

static void MX_SPI5_Init(void)
{

  /* SPI5 parameter configuration*/
  hspi5.Instance = SPI5;
  hspi5.Init.Mode = SPI_MODE_MASTER;
  hspi5.Init.Direction = SPI_DIRECTION_2LINES;
  hspi5.Init.DataSize = SPI_DATASIZE_8BIT;
  hspi5.Init.CLKPolarity = SPI_POLARITY_LOW;
  hspi5.Init.CLKPhase = SPI_PHASE_1EDGE;
  hspi5.Init.NSS = SPI_NSS_SOFT;
  hspi5.Init.BaudRatePrescaler = SPI_BAUDRATEPRESCALER_2;
  hspi5.Init.FirstBit = SPI_FIRSTBIT_MSB;
  hspi5.Init.TIMode = SPI_TIMODE_DISABLE;
  hspi5.Init.CRCCalculation = SPI_CRCCALCULATION_DISABLE;
  hspi5.Init.CRCPolynomial = 10;
  if (HAL_SPI_Init(&hspi5) != HAL_OK)
  {
    Error_Handler();
  }

}

static void MX_TIM1_Init(void)
{

  TIM_ClockConfigTypeDef sClockSourceConfig = {0};
  TIM_MasterConfigTypeDef sMasterConfig = {0};

  htim1.Instance = TIM1;
  htim1.Init.Prescaler = 0;
  htim1.Init.CounterMode = TIM_COUNTERMODE_UP;
  htim1.Init.Period = 65535;
  htim1.Init.ClockDivision = TIM_CLOCKDIVISION_DIV1;
  htim1.Init.RepetitionCounter = 0;
  htim1.Init.AutoReloadPreload = TIM_AUTORELOAD_PRELOAD_DISABLE;
  if (HAL_TIM_Base_Init(&htim1) != HAL_OK)
  {
    Error_Handler();
  }
  sClockSourceConfig.ClockSource = TIM_CLOCKSOURCE_INTERNAL;
  if (HAL_TIM_ConfigClockSource(&htim1, &sClockSourceConfig) != HAL_OK)
  {
    Error_Handler();
  }
  sMasterConfig.MasterOutputTrigger = TIM_TRGO_RESET;
  sMasterConfig.MasterSlaveMode = TIM_MASTERSLAVEMODE_DISABLE;
  if (HAL_TIMEx_MasterConfigSynchronization(&htim1, &sMasterConfig) != HAL_OK)
  {
    Error_Handler();
  }

}

static void MX_USART1_UART_Init(void)
{

  huart1.Instance = USART1;
  huart1.Init.BaudRate = 115200;
  huart1.Init.WordLength = UART_WORDLENGTH_8B;
  huart1.Init.StopBits = UART_STOPBITS_1;
  huart1.Init.Parity = UART_PARITY_NONE;
  huart1.Init.Mode = UART_MODE_TX_RX;
  huart1.Init.HwFlowCtl = UART_HWCONTROL_NONE;
  huart1.Init.OverSampling = UART_OVERSAMPLING_16;
  if (HAL_UART_Init(&huart1) != HAL_OK)
  {
    Error_Handler();
  }

}

/* FMC initialization function */
static void MX_FMC_Init(void)
{

  FMC_SDRAM_TimingTypeDef SdramTiming = {0};

  /** Perform the SDRAM1 memory initialization sequence
  */
  hsdram1.Instance = FMC_SDRAM_DEVICE;
  /* hsdram1.Init */
  hsdram1.Init.SDBank = FMC_SDRAM_BANK2;
  hsdram1.Init.ColumnBitsNumber = FMC_SDRAM_COLUMN_BITS_NUM_8;
  hsdram1.Init.RowBitsNumber = FMC_SDRAM_ROW_BITS_NUM_12;
  hsdram1.Init.MemoryDataWidth = FMC_SDRAM_MEM_BUS_WIDTH_16;
  hsdram1.Init.InternalBankNumber = FMC_SDRAM_INTERN_BANKS_NUM_4;
  hsdram1.Init.CASLatency = FMC_SDRAM_CAS_LATENCY_1;
  hsdram1.Init.WriteProtection = FMC_SDRAM_WRITE_PROTECTION_DISABLE;
  hsdram1.Init.SDClockPeriod = FMC_SDRAM_CLOCK_DISABLE;
  hsdram1.Init.ReadBurst = FMC_SDRAM_RBURST_DISABLE;
  hsdram1.Init.ReadPipeDelay = FMC_SDRAM_RPIPE_DELAY_0;
  /* SdramTiming */
  SdramTiming.LoadToActiveDelay = 16;
  SdramTiming.ExitSelfRefreshDelay = 16;
  SdramTiming.SelfRefreshTime = 16;
  SdramTiming.RowCycleDelay = 16;
  SdramTiming.WriteRecoveryTime = 16;
  SdramTiming.RPDelay = 16;
  SdramTiming.RCDDelay = 16;

  if (HAL_SDRAM_Init(&hsdram1, &SdramTiming) != HAL_OK)
  {
    Error_Handler( );
  }

}

static void MX_GPIO_Init(void)
{
  GPIO_InitTypeDef GPIO_InitStruct = {0};

  /* GPIO Ports Clock Enable */
  __HAL_RCC_GPIOE_CLK_ENABLE();
  __HAL_RCC_GPIOC_CLK_ENABLE();
  __HAL_RCC_GPIOF_CLK_ENABLE();
  __HAL_RCC_GPIOH_CLK_ENABLE();
  __HAL_RCC_GPIOA_CLK_ENABLE();
  __HAL_RCC_GPIOB_CLK_ENABLE();
  __HAL_RCC_GPIOG_CLK_ENABLE();
  __HAL_RCC_GPIOD_CLK_ENABLE();

  /*Configure GPIO pin Output Level */
  HAL_GPIO_WritePin(GPIOC, NCS_MEMS_SPI_Pin|CSX_Pin|OTG_FS_PSO_Pin, GPIO_PIN_RESET);

  /*Configure GPIO pin Output Level */
  HAL_GPIO_WritePin(ACP_RST_GPIO_Port, ACP_RST_Pin, GPIO_PIN_RESET);

  /*Configure GPIO pin Output Level */
  HAL_GPIO_WritePin(GPIOD, RDX_Pin|WRX_DCX_Pin, GPIO_PIN_RESET);

  /*Configure GPIO pin Output Level */
  HAL_GPIO_WritePin(GPIOG, led_green_Pin|led_red_Pin, GPIO_PIN_RESET);

  /*Configure GPIO pins : NCS_MEMS_SPI_Pin CSX_Pin OTG_FS_PSO_Pin */
  GPIO_InitStruct.Pin = NCS_MEMS_SPI_Pin|CSX_Pin|OTG_FS_PSO_Pin;
  GPIO_InitStruct.Mode = GPIO_MODE_OUTPUT_PP;
  GPIO_InitStruct.Pull = GPIO_NOPULL;
  GPIO_InitStruct.Speed = GPIO_SPEED_FREQ_LOW;
  HAL_GPIO_Init(GPIOC, &GPIO_InitStruct);

  /*Configure GPIO pins : B1_Pin MEMS_INT1_Pin MEMS_INT2_Pin TP_INT1_Pin */
  GPIO_InitStruct.Pin = B1_Pin|MEMS_INT1_Pin|MEMS_INT2_Pin|TP_INT1_Pin;
  GPIO_InitStruct.Mode = GPIO_MODE_EVT_RISING;
  GPIO_InitStruct.Pull = GPIO_NOPULL;
  HAL_GPIO_Init(GPIOA, &GPIO_InitStruct);

  /*Configure GPIO pin : ACP_RST_Pin */
  GPIO_InitStruct.Pin = ACP_RST_Pin;
  GPIO_InitStruct.Mode = GPIO_MODE_OUTPUT_PP;
  GPIO_InitStruct.Pull = GPIO_NOPULL;
  GPIO_InitStruct.Speed = GPIO_SPEED_FREQ_LOW;
  HAL_GPIO_Init(ACP_RST_GPIO_Port, &GPIO_InitStruct);

  /*Configure GPIO pin : OTG_FS_OC_Pin */
  GPIO_InitStruct.Pin = OTG_FS_OC_Pin;
  GPIO_InitStruct.Mode = GPIO_MODE_EVT_RISING;
  GPIO_InitStruct.Pull = GPIO_NOPULL;
  HAL_GPIO_Init(OTG_FS_OC_GPIO_Port, &GPIO_InitStruct);

  /*Configure GPIO pin : BOOT1_Pin */
  GPIO_InitStruct.Pin = BOOT1_Pin;
  GPIO_InitStruct.Mode = GPIO_MODE_INPUT;
  GPIO_InitStruct.Pull = GPIO_NOPULL;
  HAL_GPIO_Init(BOOT1_GPIO_Port, &GPIO_InitStruct);

  /*Configure GPIO pin : TE_Pin */
  GPIO_InitStruct.Pin = TE_Pin;
  GPIO_InitStruct.Mode = GPIO_MODE_INPUT;
  GPIO_InitStruct.Pull = GPIO_NOPULL;
  HAL_GPIO_Init(TE_GPIO_Port, &GPIO_InitStruct);

  /*Configure GPIO pins : RDX_Pin WRX_DCX_Pin */
  GPIO_InitStruct.Pin = RDX_Pin|WRX_DCX_Pin;
  GPIO_InitStruct.Mode = GPIO_MODE_OUTPUT_PP;
  GPIO_InitStruct.Pull = GPIO_NOPULL;
  GPIO_InitStruct.Speed = GPIO_SPEED_FREQ_LOW;
  HAL_GPIO_Init(GPIOD, &GPIO_InitStruct);

  /*Configure GPIO pins : led_green_Pin led_red_Pin */
  GPIO_InitStruct.Pin = led_green_Pin|led_red_Pin;
  GPIO_InitStruct.Mode = GPIO_MODE_OUTPUT_PP;
  GPIO_InitStruct.Pull = GPIO_NOPULL;
  GPIO_InitStruct.Speed = GPIO_SPEED_FREQ_LOW;
  HAL_GPIO_Init(GPIOG, &GPIO_InitStruct);

  /* USER CODE BEGIN MX_GPIO_Init_2 */
  /* Configure SPI4 pins: PE2=SCK, PE5=MISO, PE6=MOSI */
  GPIO_InitStruct.Pin = GPIO_PIN_2 | GPIO_PIN_5 | GPIO_PIN_6;
  GPIO_InitStruct.Mode = GPIO_MODE_AF_PP;
  GPIO_InitStruct.Pull = GPIO_NOPULL;
  GPIO_InitStruct.Speed = GPIO_SPEED_FREQ_VERY_HIGH;
  GPIO_InitStruct.Alternate = GPIO_AF5_SPI4;
  HAL_GPIO_Init(GPIOE, &GPIO_InitStruct);
  /* USER CODE END MX_GPIO_Init_2 */
}

/* USER CODE BEGIN 4 */
/* 5x7 šriftas (ASCII 32–127) */
static const uint8_t font5x7[][5] = {
    {0x00,0x00,0x00,0x00,0x00}, /* ' ' */
    {0x00,0x00,0x5F,0x00,0x00}, /* '!' */
    {0x00,0x07,0x00,0x07,0x00}, /* '"' */
    {0x14,0x7F,0x14,0x7F,0x14}, /* '#' */
    {0x24,0x2A,0x7F,0x2A,0x12}, /* '$' */
    {0x23,0x13,0x08,0x64,0x62}, /* '%' */
    {0x36,0x49,0x55,0x22,0x50}, /* '&' */
    {0x00,0x05,0x03,0x00,0x00}, /* ''' */
    {0x00,0x1C,0x22,0x41,0x00}, /* '(' */
    {0x00,0x41,0x22,0x1C,0x00}, /* ')' */
    {0x14,0x08,0x3E,0x08,0x14}, /* '*' */
    {0x08,0x08,0x3E,0x08,0x08}, /* '+' */
    {0x00,0x50,0x30,0x00,0x00}, /* ',' */
    {0x08,0x08,0x08,0x08,0x08}, /* '-' */
    {0x00,0x60,0x60,0x00,0x00}, /* '.' */
    {0x20,0x10,0x08,0x04,0x02}, /* '/' */
    {0x3E,0x51,0x49,0x45,0x3E}, /* '0' */
    {0x00,0x42,0x7F,0x40,0x00}, /* '1' */
    {0x42,0x61,0x51,0x49,0x46}, /* '2' */
    {0x21,0x41,0x45,0x4B,0x31}, /* '3' */
    {0x18,0x14,0x12,0x7F,0x10}, /* '4' */
    {0x27,0x45,0x45,0x45,0x39}, /* '5' */
    {0x3C,0x4A,0x49,0x49,0x30}, /* '6' */
    {0x01,0x71,0x09,0x05,0x03}, /* '7' */
    {0x36,0x49,0x49,0x49,0x36}, /* '8' */
    {0x06,0x49,0x49,0x29,0x1E}, /* '9' */
    {0x00,0x36,0x36,0x00,0x00}, /* ':' */
    {0x00,0x56,0x36,0x00,0x00}, /* ';' */
    {0x08,0x14,0x22,0x41,0x00}, /* '<' */
    {0x14,0x14,0x14,0x14,0x14}, /* '=' */
    {0x00,0x41,0x22,0x14,0x08}, /* '>' */
    {0x02,0x01,0x51,0x09,0x06}, /* '?' */
    {0x32,0x49,0x79,0x41,0x3E}, /* '@' */
    {0x7E,0x11,0x11,0x11,0x7E}, /* 'A' */
    {0x7F,0x49,0x49,0x49,0x36}, /* 'B' */
    {0x3E,0x41,0x41,0x41,0x22}, /* 'C' */
    {0x7F,0x41,0x41,0x22,0x1C}, /* 'D' */
    {0x7F,0x49,0x49,0x49,0x41}, /* 'E' */
    {0x7F,0x09,0x09,0x09,0x01}, /* 'F' */
    {0x3E,0x41,0x49,0x49,0x7A}, /* 'G' */
    {0x7F,0x08,0x08,0x08,0x7F}, /* 'H' */
    {0x00,0x41,0x7F,0x41,0x00}, /* 'I' */
    {0x20,0x40,0x41,0x3F,0x01}, /* 'J' */
    {0x7F,0x08,0x14,0x22,0x41}, /* 'K' */
    {0x7F,0x40,0x40,0x40,0x40}, /* 'L' */
    {0x7F,0x02,0x0C,0x02,0x7F}, /* 'M' */
    {0x7F,0x04,0x08,0x10,0x7F}, /* 'N' */
    {0x3E,0x41,0x41,0x41,0x3E}, /* 'O' */
    {0x7F,0x09,0x09,0x09,0x06}, /* 'P' */
    {0x3E,0x41,0x51,0x21,0x5E}, /* 'Q' */
    {0x7F,0x09,0x19,0x29,0x46}, /* 'R' */
    {0x46,0x49,0x49,0x49,0x31}, /* 'S' */
    {0x01,0x01,0x7F,0x01,0x01}, /* 'T' */
    {0x3F,0x40,0x40,0x40,0x3F}, /* 'U' */
    {0x1F,0x20,0x40,0x20,0x1F}, /* 'V' */
    {0x3F,0x40,0x38,0x40,0x3F}, /* 'W' */
    {0x63,0x14,0x08,0x14,0x63}, /* 'X' */
    {0x07,0x08,0x70,0x08,0x07}, /* 'Y' */
    {0x61,0x51,0x49,0x45,0x43}, /* 'Z' */
    {0x00,0x7F,0x41,0x41,0x00}, /* '[' */
    {0x02,0x04,0x08,0x10,0x20}, /* '\' */
    {0x00,0x41,0x41,0x7F,0x00}, /* ']' */
    {0x04,0x02,0x01,0x02,0x04}, /* '^' */
    {0x40,0x40,0x40,0x40,0x40}, /* '_' */
    {0x00,0x01,0x02,0x04,0x00}, /* '`' */
    {0x20,0x54,0x54,0x54,0x78}, /* 'a' */
    {0x7F,0x48,0x44,0x44,0x38}, /* 'b' */
    {0x38,0x44,0x44,0x44,0x20}, /* 'c' */
    {0x38,0x44,0x44,0x48,0x7F}, /* 'd' */
    {0x38,0x54,0x54,0x54,0x18}, /* 'e' */
    {0x08,0x7E,0x09,0x01,0x02}, /* 'f' */
    {0x0C,0x52,0x52,0x52,0x3E}, /* 'g' */
    {0x7F,0x08,0x04,0x04,0x78}, /* 'h' */
    {0x00,0x44,0x7D,0x40,0x00}, /* 'i' */
    {0x20,0x40,0x44,0x3D,0x00}, /* 'j' */
    {0x7F,0x10,0x28,0x44,0x00}, /* 'k' */
    {0x00,0x41,0x7F,0x40,0x00}, /* 'l' */
    {0x7C,0x04,0x18,0x04,0x78}, /* 'm' */
    {0x7C,0x08,0x04,0x04,0x78}, /* 'n' */
    {0x38,0x44,0x44,0x44,0x38}, /* 'o' */
    {0x7C,0x14,0x14,0x14,0x08}, /* 'p' */
    {0x08,0x14,0x14,0x18,0x7C}, /* 'q' */
    {0x7C,0x08,0x04,0x04,0x08}, /* 'r' */
    {0x48,0x54,0x54,0x54,0x20}, /* 's' */
    {0x04,0x3F,0x44,0x40,0x20}, /* 't' */
    {0x3C,0x40,0x40,0x40,0x7C}, /* 'u' */
    {0x1C,0x20,0x40,0x20,0x1C}, /* 'v' */
    {0x3C,0x40,0x30,0x40,0x3C}, /* 'w' */
    {0x44,0x28,0x10,0x28,0x44}, /* 'x' */
    {0x0C,0x50,0x50,0x50,0x3C}, /* 'y' */
    {0x44,0x64,0x54,0x4C,0x44}, /* 'z' */
    {0x00,0x08,0x36,0x41,0x00}, /* '{' */
    {0x00,0x00,0x7F,0x00,0x00}, /* '|' */
    {0x00,0x41,0x36,0x08,0x00}, /* '}' */
    {0x10,0x08,0x08,0x10,0x08}, /* '~' */
};

/* --- Žemo lygio SPI pagalbinės funkcijos --- */

static void LCD_WriteCommand(uint8_t cmd)
{
    LCD_DC_LOW();
    LCD_CS_LOW();
    HAL_SPI_Transmit(&hspi5, &cmd, 1, 10);
    LCD_CS_HIGH();
}

static void LCD_WriteData(uint8_t data)
{
    LCD_DC_HIGH();
    LCD_CS_LOW();
    HAL_SPI_Transmit(&hspi5, &data, 1, 10);
    LCD_CS_HIGH();
}

static void LCD_WriteData16(uint16_t data)
{
    uint8_t buf[2] = { (uint8_t)(data >> 8), (uint8_t)(data & 0xFF) };
    LCD_DC_HIGH();
    LCD_CS_LOW();
    HAL_SPI_Transmit(&hspi5, buf, 2, 10);
    LCD_CS_HIGH();
}

/* --- ILI9341 inicijavimas --- */

static void LCD_Init(void)
{
    /* Aparatūrinis reset */
	/* Rankiniu būdu CS = HIGH prieš reset */
	    LCD_CS_HIGH();
	    HAL_Delay(10);

	    /* Aparatūrinis reset */
	    LCD_RST_LOW();
	    HAL_Delay(20);
	    LCD_RST_HIGH();
	    HAL_Delay(120);

    LCD_WriteCommand(0xCA);
    LCD_WriteData(0xC3); LCD_WriteData(0x08); LCD_WriteData(0x50);

    LCD_WriteCommand(ILI9341_POWERB);
    LCD_WriteData(0x00); LCD_WriteData(0xC1); LCD_WriteData(0x30);

    LCD_WriteCommand(ILI9341_POWER_SEQ);
    LCD_WriteData(0x64); LCD_WriteData(0x03);
    LCD_WriteData(0x12); LCD_WriteData(0x81);

    LCD_WriteCommand(ILI9341_DTCA);
    LCD_WriteData(0x85); LCD_WriteData(0x00); LCD_WriteData(0x78);

    LCD_WriteCommand(ILI9341_POWERA);
    LCD_WriteData(0x39); LCD_WriteData(0x2C); LCD_WriteData(0x00);
    LCD_WriteData(0x34); LCD_WriteData(0x02);

    LCD_WriteCommand(ILI9341_PRC);
    LCD_WriteData(0x20);

    LCD_WriteCommand(ILI9341_DTCB);
    LCD_WriteData(0x00); LCD_WriteData(0x00);

    LCD_WriteCommand(ILI9341_POWER1);
    LCD_WriteData(0x1B);

    LCD_WriteCommand(ILI9341_POWER2);
    LCD_WriteData(0x12);

    LCD_WriteCommand(ILI9341_VCOM1);
    LCD_WriteData(0x08); LCD_WriteData(0x26);

    LCD_WriteCommand(ILI9341_VCOM2);
    LCD_WriteData(0xB7);

    LCD_WriteCommand(ILI9341_PIXEL_FORMAT);
    LCD_WriteData(0x55); /* 16 bpp */

    LCD_WriteCommand(ILI9341_MAC);
    LCD_WriteData(0x08); /* MX=0, MY=0, MV=0 – portretinis */

    LCD_WriteCommand(ILI9341_FRC);
    LCD_WriteData(0x00); LCD_WriteData(0x1B);

    LCD_WriteCommand(ILI9341_DFC);
    LCD_WriteData(0x0A); LCD_WriteData(0xA2);

    LCD_WriteCommand(ILI9341_3GAMMA_EN);
    LCD_WriteData(0x02);

    LCD_WriteCommand(ILI9341_GAMMA);
    LCD_WriteData(0x01);

    LCD_WriteCommand(ILI9341_PGAMMA);
    LCD_WriteData(0x0F); LCD_WriteData(0x1D); LCD_WriteData(0x19);
    LCD_WriteData(0x0E); LCD_WriteData(0x10); LCD_WriteData(0x07);
    LCD_WriteData(0x4B); LCD_WriteData(0x83); LCD_WriteData(0x3C);
    LCD_WriteData(0x07); LCD_WriteData(0x0E); LCD_WriteData(0x00);
    LCD_WriteData(0x00); LCD_WriteData(0x00); LCD_WriteData(0x00);

    LCD_WriteCommand(ILI9341_NGAMMA);
    LCD_WriteData(0x00); LCD_WriteData(0x22); LCD_WriteData(0x26);
    LCD_WriteData(0x11); LCD_WriteData(0x0F); LCD_WriteData(0x08);
    LCD_WriteData(0x34); LCD_WriteData(0x42); LCD_WriteData(0x43);
    LCD_WriteData(0x08); LCD_WriteData(0x11); LCD_WriteData(0x0F);
    LCD_WriteData(0x3F); LCD_WriteData(0x3F); LCD_WriteData(0x0F);

    LCD_WriteCommand(ILI9341_SLEEP_OUT);
    HAL_Delay(120);
    LCD_WriteCommand(ILI9341_DISPLAY_ON);
    HAL_Delay(10);
}

/* --- Grafikos funkcijos --- */

static void LCD_SetWindow(uint16_t x0, uint16_t y0, uint16_t x1, uint16_t y1)
{
    LCD_WriteCommand(ILI9341_COLUMN_ADDR);
    LCD_WriteData(x0 >> 8); LCD_WriteData(x0 & 0xFF);
    LCD_WriteData(x1 >> 8); LCD_WriteData(x1 & 0xFF);

    LCD_WriteCommand(ILI9341_PAGE_ADDR);
    LCD_WriteData(y0 >> 8); LCD_WriteData(y0 & 0xFF);
    LCD_WriteData(y1 >> 8); LCD_WriteData(y1 & 0xFF);

    LCD_WriteCommand(ILI9341_GRAM);
}

static void LCD_FillRect(uint16_t x, uint16_t y, uint16_t w, uint16_t h, uint16_t color)
{
    uint8_t hi = color >> 8, lo = color & 0xFF;
    LCD_SetWindow(x, y, x + w - 1, y + h - 1);
    LCD_DC_HIGH();
    LCD_CS_LOW();
    for (uint32_t i = 0; i < (uint32_t)w * h; i++) {
        HAL_SPI_Transmit(&hspi5, &hi, 1, 5);
        HAL_SPI_Transmit(&hspi5, &lo, 1, 5);
    }
    LCD_CS_HIGH();
}

static void LCD_FillScreen(uint16_t color)
{
    LCD_FillRect(0, 0, LCD_WIDTH, LCD_HEIGHT, color);
}

static void LCD_DrawPixel(uint16_t x, uint16_t y, uint16_t color)
{
    LCD_SetWindow(x, y, x, y);
    LCD_WriteData16(color);
}

static void LCD_DrawLine(uint16_t x0, uint16_t y0, uint16_t x1, uint16_t y1, uint16_t color)
{
    int16_t dx = (int16_t)(x1 - x0), dy = (int16_t)(y1 - y0);
    int16_t sx = dx > 0 ? 1 : -1, sy = dy > 0 ? 1 : -1;
    dx = dx < 0 ? -dx : dx;
    dy = dy < 0 ? -dy : dy;
    int16_t err = dx - dy, e2;
    for (;;) {
        LCD_DrawPixel(x0, y0, color);
        if (x0 == x1 && y0 == y1) break;
        e2 = 2 * err;
        if (e2 > -dy) { err -= dy; x0 += sx; }
        if (e2 <  dx) { err += dx; y0 += sy; }
    }
}

static void LCD_DrawRect(uint16_t x, uint16_t y, uint16_t w, uint16_t h, uint16_t color)
{
    LCD_DrawLine(x,       y,       x+w-1, y,       color);
    LCD_DrawLine(x,       y+h-1,   x+w-1, y+h-1,   color);
    LCD_DrawLine(x,       y,       x,     y+h-1,   color);
    LCD_DrawLine(x+w-1,   y,       x+w-1, y+h-1,   color);
}

static void LCD_DrawChar(uint16_t x, uint16_t y, char c,
                         uint16_t fg, uint16_t bg, uint8_t size)
{
    if (c < 32 || c > 126) c = '?';
    const uint8_t *glyph = font5x7[c - 32];
    for (uint8_t col = 0; col < 5; col++) {
        uint8_t line = glyph[col];
        for (uint8_t row = 0; row < 7; row++) {
            uint16_t color = (line & (1 << row)) ? fg : bg;
            if (size == 1) {
                LCD_DrawPixel(x + col, y + row, color);
            } else {
                LCD_FillRect(x + col * size, y + row * size, size, size, color);
            }
        }
    }
    /* tarpas tarp simbolių */
    if (size == 1)
        LCD_DrawLine(x+5, y, x+5, y+6, bg);
    else
        LCD_FillRect(x + 5*size, y, size, 7*size, bg);
}

static void LCD_DrawString(uint16_t x, uint16_t y, const char *str,
                           uint16_t fg, uint16_t bg, uint8_t size)
{
    uint16_t cx = x;
    while (*str) {
        LCD_DrawChar(cx, y, *str++, fg, bg, size);
        cx += 6 * size;
    }
}

/* -------------------------------------------------------
 * Pagrindinė demonstracinė funkcija
 * Kvieskite iš StartDefaultTask po HAL_SPI_TransmitReceive
 * ------------------------------------------------------- */
static void SPI_Demo_Display(uint8_t *tx, uint8_t *rx, HAL_StatusTypeDef status)
{
    char buf[40];

    /* Fonas */
    LCD_FillScreen(COLOR_BLACK);

    /* Viršutinė juosta */
    LCD_FillRect(0, 0, LCD_WIDTH, 26, COLOR_BLUE);
    LCD_DrawString(18, 8, "SPI4 LOOPBACK TEST", COLOR_WHITE, COLOR_BLUE, 1);

    /* TX sekcija */
    LCD_FillRect(0, 30, LCD_WIDTH, 18, 0x1082); /* tamsiai pilka */
    LCD_DrawString(4, 36, "TX:", COLOR_YELLOW, 0x1082, 1);
    snprintf(buf, sizeof(buf), "%3d %3d %3d %3d", tx[0], tx[1], tx[2], tx[3]);
    LCD_DrawString(30, 36, buf, COLOR_YELLOW, 0x1082, 1);

    /* Rodyklė */
    LCD_DrawString(110, 55, "v", COLOR_CYAN, COLOR_BLACK, 2);

    /* RX sekcija */
    LCD_FillRect(0, 78, LCD_WIDTH, 18, 0x1082);
    LCD_DrawString(4, 84, "RX:", COLOR_GREEN, 0x1082, 1);
    snprintf(buf, sizeof(buf), "%3d %3d %3d %3d", rx[0], rx[1], rx[2], rx[3]);
    LCD_DrawString(30, 84, buf, COLOR_GREEN, 0x1082, 1);

    /* Sutapimo tikrinimas */
    uint8_t match = (tx[0]==rx[0]) && (tx[1]==rx[1]) &&
                    (tx[2]==rx[2]) && (tx[3]==rx[3]);

    LCD_FillRect(0, 106, LCD_WIDTH, 22, match ? 0x03E0 : 0x6000);
    if (match) {
        LCD_DrawString(52, 113, "MATCH OK!", COLOR_BLACK, 0x03E0, 1);
    } else {
        LCD_DrawString(38, 113, "MISMATCH!", COLOR_WHITE, 0x6000, 1);
    }

    /* Statusas */
    LCD_DrawString(4, 136, "HAL status:", COLOR_WHITE, COLOR_BLACK, 1);
    const char *stext = (status == HAL_OK)      ? "HAL_OK"      :
                        (status == HAL_ERROR)    ? "HAL_ERROR"   :
                        (status == HAL_BUSY)     ? "HAL_BUSY"    : "HAL_TIMEOUT";
    uint16_t sc = (status == HAL_OK) ? COLOR_GREEN : COLOR_RED;
    LCD_DrawString(74, 136, stext, sc, COLOR_BLACK, 1);

    /* Apvadas */
    LCD_DrawRect(0, 0, LCD_WIDTH, 155, COLOR_BLUE);

    /* Atskiriamoji linija */
    LCD_DrawLine(0, 162, LCD_WIDTH, 162, 0x39E7);

    /* Instrukcija debug'ui */
    LCD_DrawString(4, 168, "Stebeti 'Live Expr.':", COLOR_WHITE, COLOR_BLACK, 1);
    LCD_DrawString(4, 180, " tx_data[0..3]",       0xFD20,      COLOR_BLACK, 1);
    LCD_DrawString(4, 192, " rx_data[0..3]",        COLOR_GREEN, COLOR_BLACK, 1);
    LCD_DrawString(4, 204, " spi_status",           COLOR_CYAN,  COLOR_BLACK, 1);

    /* SPI4 išvadų schema */
    LCD_DrawString(4, 220, "SPI4 wiring:", COLOR_WHITE, COLOR_BLACK, 1);
    LCD_DrawString(4, 232, " PE6(MOSI) -> PE5(MISO)", 0xFD20, COLOR_BLACK, 1);
    LCD_DrawString(4, 244, " PE2 = SCK",              0xFD20, COLOR_BLACK, 1);
}
/* USER CODE END 4 */

void StartDefaultTask(void const * argument)
{

	    //MX_USB_HOST_Init();
	    for(;;)
	        {
	            HAL_GPIO_TogglePin(GPIOG, led_green_Pin);
	            osDelay(500);
	        }

//  MX_USB_HOST_Init();
//
//  LCD_Init();
//  LCD_FillScreen(COLOR_BLACK);
//
//  for(;;)
//  {
//    rx_data[0] = rx_data[1] = rx_data[2] = rx_data[3] = 0;
//
//    spi_status = HAL_SPI_TransmitReceive(&hspi4, tx_data, rx_data, 4, 100);
//
//    SPI_Demo_Display(tx_data, rx_data, spi_status);
//
//    HAL_GPIO_TogglePin(GPIOG, led_green_Pin);
//    osDelay(500);
//  }
}
  /* USER CODE END 5 */

void Error_Handler(void)
{
  __disable_irq();
  while (1)
  {
  }
}
